# R40 register map
Vendor: Allwinner; Series: R40; File version: 0.1
CPU: CA7 0, little endian, MPU, FPU, double-precision FPU, 0 interrupt priority bits
Registers are 32-bit, read-write, reset 0x0 unless marked. A register's access mark holds for its fields unless they carry their own. Offsets are from the block's base; [hi:lo] are bit positions; {n}, {i} and the like mark numbered series; 'fields as' and 'values as' point back to an identical list.

## CCU (part 1 of 2)
Base 0x01C20000
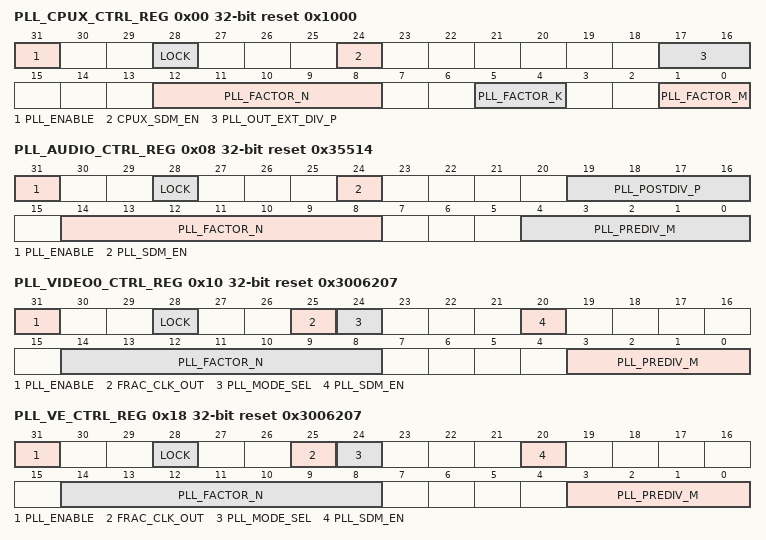
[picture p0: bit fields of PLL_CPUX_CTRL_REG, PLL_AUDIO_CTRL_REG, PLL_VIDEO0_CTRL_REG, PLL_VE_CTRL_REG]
0x00 PLL_CPUX_CTRL_REG reset 0x1000 — PLL_CPUX Control Register
  [31] PLL_ENABLE — 0: Disable 1: Enable. The PLL _CPUX = ((24MHz/K)*N)/(M*P). The PLL output is for the CPUX Clock. Note: 10<=N*K<=88. 24MHz*N*K must be in the range of 240MHz~2.1GHz. The default value of PLL _CPUX is 408MHz.
    0=Disable; 1=Enable. The PLL _CPUX = ((24MHz/K)*N)/(M*P). The PLL output is for the CPUX Clock. Note: 10<=N*K<=88. 24MHz*N*K must be in the range of 240MHz~2.1GHz. The default value of PLL _CPUX is 408MHz.
  [28] LOCK ro — 0: Unlocked 1: Locked (It indicates that the PLL has been stable.)
    0=Unlocked; 1=Locked (It indicates that the PLL has been stable.)
  [24] CPUX_SDM_EN — 0: Disable 1: Enable.
    0=Disable; 1=Enable
  [17:16] PLL_OUT_EXT_DIV_P — PLL Output External Divider P 00: /1 01: /2 10: /4 11: /.
    0=_slash_1 (/1); 1=_slash_2 (/2); 2=_slash_4 (/4); 3=_slash_
  [12:8] PLL_FACTOR_N — PLL Factor N. Factor=0, N=1 Factor=1, N=2 Factor=2, N=3 ... Factor=31,N=32.
  [5:4] PLL_FACTOR_K — PLL Factor K. (K=Factor + 1) The range is from 1 to 4.
  [1:0] PLL_FACTOR_M — PLL Factor M. (M=Factor + 1) The range is from 1 to 4.
0x08 PLL_AUDIO_CTRL_REG reset 0x35514 — PLL_AUDIO Control Register
  [31] PLL_ENABLE — 0: Disable 1: Enable. The PLL is for Audio. The PLL_AUDIO= (24MHz*N)/(M*P). The PLL_AUDIO(8X) = (24MHz*N*2)/M Note: 3<=N/M<=21. (24MHz*N)/P must be in the range of 72MHz~504MHz . PLL_AUDIO default is 24.571MHz.
    0=Disable; 1=Enable. The PLL is for Audio. The PLL_AUDIO= (24MHz*N)/(M*P). The PLL_AUDIO(8X) = (24MHz*N*2)/M Note: 3<=N/M<=21. (24MHz*N)/P must be in the range of 72MHz~504MHz . PLL_AUDIO default is 24.571MHz.
  [28] LOCK ro — 0: Unlocked 1: Locked (It indicates that the PLL has been stable.)
    values as PLL_CPUX_CTRL_REG.LOCK
  [24] PLL_SDM_EN — 0: Disable 1: Enable. In this case, the only low 4 bits of are valid (N: The range is from 1 to 16).
    0=Disable; 1=Enable. In this case, the only low 4 bits of are valid (N: The range is from 1 to 16).
  [19:16] PLL_POSTDIV_P — Post-div factor (P= Factor+1) The range is from 1 to 16.
  [14:8] PLL_FACTOR_N — PLL Factor N. Factor=0, N=1 Factor=1, N=2 ... Factor=127, N=128.
  [4:0] PLL_PREDIV_M — PLL Pre-div Factor(M = Factor+1). The range is from 1 to 32.
0x10 PLL_VIDEO0_CTRL_REG reset 0x3006207 — PLL_VIDEO0 Control Register
  [31] PLL_ENABLE — 0: Disable 1: Enable. In the integer mode, PLL_VIDEO0(1X) = (24MHz*N)/M. PLL_VIDEO0(2X) =( (24MHz*N)/M)*2. In the fractional mode, the PLL Output is select by bit 25. Note: 8<=N/M<=25 (24MHz*N)/M must be in the range of 192MHz~600MHz. PLL_VIDEO0(1X) default is 297MHz.
    0=Disable; 1=Enable. In the integer mode, PLL_VIDEO0(1X) = (24MHz*N)/M. PLL_VIDEO0(2X) =( (24MHz*N)/M)*2. In the fractional mode, the PLL Output is select by bit 25. Note: 8<=N/M<=25 (24MHz*N)/M must be in the range of 192MHz~600MHz. PLL_VIDEO0(1X) default is 297MHz.
  [28] LOCK ro — 0: Unlocked 1: Locked (It indicates that the PLL has been stable.)
    values as PLL_CPUX_CTRL_REG.LOCK
  [25] FRAC_CLK_OUT — PLL clock output when =0( factor must be set to 0); No meaning when =1. 0: PLL Output=270MHz 1: PLL Output =297MHz.
    0=PLL_Output_equals_270MHz (PLL Output=270MHz); 1=PLL Output =297MHz
  [24] PLL_MODE_SEL — 0: Fractional Mode 1: Integer Mode. Note: When in Fractional mode, the Pre Divider M should be set to 0.
    0=Fractional Mode; 1=Integer Mode. Note: When in Fractional mode, the Pre Divider M should be set to 0.
  [20] PLL_SDM_EN — 0: Disable 1: Enable.
    0=Disable; 1=Enable
  [14:8] PLL_FACTOR_N — PLL Factor N. Factor=0, N=1 Factor=1, N=2 Factor=2, N=3 ... Factor=127,N=128.
  [3:0] PLL_PREDIV_M — PLL Pre-div Factor(M = Factor+1). The range is from 1 to 16.
0x18 PLL_VE_CTRL_REG reset 0x3006207 — PLL_VE Control Register
  [31] PLL_ENABLE — 0: Disable 1: Enable. In the integer mode, The PLL_VE = (24MHz*N)/M. In the fractional mode, the PLL Output is select by . Note: 8<=N/M<=25 (24MHz*N)/M must be in the range of 192MHz~600MHz. The default value of PLL_VE is 297MHz.
    0=Disable; 1=Enable. In the integer mode, The PLL_VE = (24MHz*N)/M. In the fractional mode, the PLL Output is select by . Note: 8<=N/M<=25 (24MHz*N)/M must be in the range of 192MHz~600MHz. The default value of PLL_VE is 297MHz.
  [28] LOCK ro — 0: Unlocked 1: Locked (It indicates that the PLL has been stable.)
    values as PLL_CPUX_CTRL_REG.LOCK
  [25] FRAC_CLK_OUT — PLL clock output when =0( factor must be set to 0); No meaning when =1. 0: PLL Output = 270MHz 1: PLL Output = 297MHz.
    0=PLL_Output__equals__270MHz (PLL Output = 270MHz); 1=PLL_Output__equals__297MHz (PLL Output = 297MHz.)
  [24] PLL_MODE_SEL — 0: Fractional Mode 1: Integer Mode. Note: When in Fractional mode, the Pre Divider M should be set to 0.
    values as PLL_VIDEO0_CTRL_REG.PLL_MODE_SEL
  [20] PLL_SDM_EN — 0: Disable 1: Enable.
    0=Disable; 1=Enable
  [14:8] PLL_FACTOR_N — PLL Factor N. Factor=0, N=1 Factor=1, N=2 Factor=2, N=3 ... Factor=31,N=32 ... Factor=127,N=128.
  [3:0] PLL_PREDIV_M — PLL Pre-div Factor(M = Factor+1). The range is from 1 to 16.
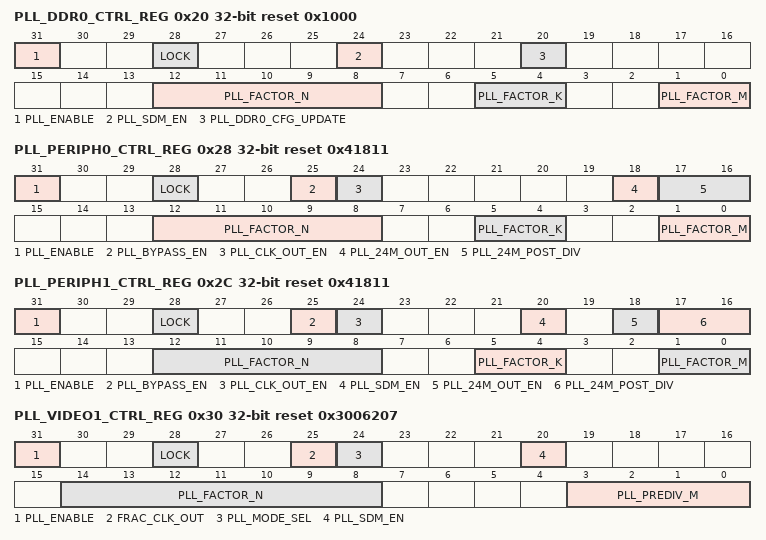
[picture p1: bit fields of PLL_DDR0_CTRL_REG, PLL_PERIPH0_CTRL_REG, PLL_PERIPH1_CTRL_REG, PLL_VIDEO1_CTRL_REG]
0x20 PLL_DDR0_CTRL_REG reset 0x1000 — PLL_DDR0 Control Register
  [31] PLL_ENABLE — 0: Disable 1: Enable. The PLL_DDR0 = (24MHz*N*K)/M. Note: 10<=N*K<=77 (24MHz*N*K) must be in the range of 240MHz~1.8GHz. The default value of PLL_DDR0 is 408MHz.
    0=Disable; 1=Enable. The PLL_DDR0 = (24MHz*N*K)/M. Note: 10<=N*K<=77 (24MHz*N*K) must be in the range of 240MHz~1.8GHz. The default value of PLL_DDR0 is 408MHz.
  [28] LOCK ro — 0: Unlocked 1: Locked (It indicates that the PLL has been stable.)
    values as PLL_CPUX_CTRL_REG.LOCK
  [24] PLL_SDM_EN — 0: Disable 1: Enable.
    0=Disable; 1=Enable
  [20] PLL_DDR0_CFG_UPDATE — PLL_DDR0 Configuration Update. When PLL_DDR0 has been changed, this bit should be set to 1 to validate the PLL, otherwise the change would be invalid. And this bit would be cleared automatically after the PLL change is valid. 0: No effect 1: Validating the PLL_DDR0.
    0=No_effect; 1=Validating the PLL_DDR0
  [12:8] PLL_FACTOR_N — PLL Factor N. Factor=0, N=1 Factor=1, N=2 Factor=2, N=3 ... Factor=31,N=32.
  [5:4] PLL_FACTOR_K — PLL Factor K.(K=Factor + 1 ) The range is from 1 to 4.
  [1:0] PLL_FACTOR_M — PLL Factor M.(M = Factor + 1 ) The range is from 1 to 4.
0x28 PLL_PERIPH0_CTRL_REG reset 0x41811 — PLL_PERIPH0 Control Register
  [31] PLL_ENABLE — 0: Disable 1: Enable. For SATA module, the output is: The PLL_PERIPH0 = 24MHz*N*K/(M*6). For other modules, the output is: The PLL_PERIPH0(1X) = 24MHz*N*K/2. The PLL_PERIPH0(2X) = 24MHz*N*K. Note: 21<=N*K<=58 The PLL_PERIPH0(2X) should be fixed to 1.2GHz, it is not recommended to vary this value arbitrarily. 24MHz*N*K clock must be in the range of 504MHz~1.4GHz. The default value of PLL_PERIPH0(2X) is 1.2GHz.
    0=Disable; 1=Enable. For SATA module, the output is: The PLL_PERIPH0 = 24MHz*N*K/(M*6). For other modules, the output is: The PLL_PERIPH0(1X) = 24MHz*N*K/2. The PLL_PERIPH0(2X) = 24MHz*N*K. Note: 21<=N*K<=58 The PLL_PERIPH0(2X) should be fixed to 1.2GHz, it is not recommended to vary this value arbitrarily. 24MHz*N*K clock must be in the range of 504MHz~1.4GHz. The default value of PLL_PERIPH0(2X) is 1.2GHz.
  [28] LOCK ro — 0: Unlocked 1: Locked (It indicates that the PLL has been stable.)
    values as PLL_CPUX_CTRL_REG.LOCK
  [25] PLL_BYPASS_EN — PLL Output Bypass Enable. 0: Disable 1: Enable. If the bypass is enabled, the PLL output is 24MHz.
    0=Disable; 1=Enable. If the bypass is enabled, the PLL output is 24MHz.
  [24] PLL_CLK_OUT_EN — PLL clock output enable.(Just for the SATA Phy) 0: Disable 1: Enable.
    0=Disable; 1=Enable
  [18] PLL_24M_OUT_EN — PLL 24MHz Output Enable. 0: Disable 1: Enable. When 25MHz crystal used, this PLL can output 24MHz.
    0=Disable; 1=Enable. When 25MHz crystal used, this PLL can output 24MHz.
  [17:16] PLL_24M_POST_DIV — PLL 24M Output Clock Post Divider (When 25MHz crystal used). 1/2/3/4.
  [12:8] PLL_FACTOR_N — PLL Factor N. Factor=0, N=1 Factor=1, N=2 Factor=2, N=3 ... Factor=31,N=32.
  [5:4] PLL_FACTOR_K — PLL Factor K.(K=Factor + 1 ) The range is from 1 to 4.
  [1:0] PLL_FACTOR_M — The range is from 1 to 4.
0x2C PLL_PERIPH1_CTRL_REG reset 0x41811 — PLL_PERIPH1 Control Register
  [31] PLL_ENABLE — 0: Disable 1: Enable. The PLL_PERIPH1(1X) = 24MHz*N*K/2. The PLL_PERIPH1(2X) = 24MHz*N*K. Note: 21<=N*K<=58 PLL_PERIPH1(2X) should be fixed to 1.2GHz, it is not recommended to vary this value arbitrarily. 24MHz*N*K must be in the range of 504MHz~1.4GHz. The default value of PLL_PERIPH1(2X) is 1.2GHz.
    0=Disable; 1=Enable. The PLL_PERIPH1(1X) = 24MHz*N*K/2. The PLL_PERIPH1(2X) = 24MHz*N*K. Note: 21<=N*K<=58 PLL_PERIPH1(2X) should be fixed to 1.2GHz, it is not recommended to vary this value arbitrarily. 24MHz*N*K must be in the range of 504MHz~1.4GHz. The default value of PLL_PERIPH1(2X) is 1.2GHz.
  [28] LOCK ro — 0: Unlocked 1: Locked (It indicates that the PLL has been stable.)
    values as PLL_CPUX_CTRL_REG.LOCK
  [25] PLL_BYPASS_EN — PLL Output Bypass Enable. 0: Disable 1: Enable. If the bypass is enabled, the PLL output is 24MHz.
    values as PLL_PERIPH0_CTRL_REG.PLL_BYPASS_EN
  [24] PLL_CLK_OUT_EN — PLL clock output enable.(Just for the SATA Phy) 0: Disable 1: Enable.
    0=Disable; 1=Enable
  [20] PLL_SDM_EN — 0: Disable 1: Enable.
    0=Disable; 1=Enable
  [18] PLL_24M_OUT_EN — PLL 24MHz Output Enable. 0: Disable 1: Enable. When 25MHz crystal used, this PLL can output 24MHz.
    values as PLL_PERIPH0_CTRL_REG.PLL_24M_OUT_EN
  [17:16] PLL_24M_POST_DIV — PLL 24M Output Clock Post Divider (When 25MHz crystal used). 1/2/3/4.
  [12:8] PLL_FACTOR_N — PLL Factor N. Factor=0, N=1 Factor=1, N=2 Factor=2, N=3 ... Factor=31,N=32.
  [5:4] PLL_FACTOR_K — PLL Factor K.(K=Factor + 1 ) The range is from 1 to 4.
  [1:0] PLL_FACTOR_M — The range is from 1 to 4.
0x30 PLL_VIDEO1_CTRL_REG reset 0x3006207 — PLL_VIDEO1 Control Register
  [31] PLL_ENABLE — 0: Disable 1: Enable. In the integer mode, PLL_VIDEO1(1X) = (24MHz*N)/M. PLL_VIDEO1(2X) =( (24MHz*N)/M)*2. In the fractional mode, the PLL Output is selected by . Note: 8<=N/M<=25 (24MHz*N)/M must be in the range of 192MHz~600MHz. The default value of PLL_VIDEO1(1X) is 297MHz.
    0=Disable; 1=Enable. In the integer mode, PLL_VIDEO1(1X) = (24MHz*N)/M. PLL_VIDEO1(2X) =( (24MHz*N)/M)*2. In the fractional mode, the PLL Output is selected by . Note: 8<=N/M<=25 (24MHz*N)/M must be in the range of 192MHz~600MHz. The default value of PLL_VIDEO1(1X) is 297MHz.
  [28] LOCK ro — 0: Unlocked 1: Locked (It indicates that the PLL has been stable.)
    values as PLL_CPUX_CTRL_REG.LOCK
  [25] FRAC_CLK_OUT — PLL clock output when =0( factor must be set to 0); No meaning when =1. 0: PLL Output=270MHz 1: PLL Output =297MHz.
    values as PLL_VIDEO0_CTRL_REG.FRAC_CLK_OUT
  [24] PLL_MODE_SEL — 0: Fractional Mode 1: Integer Mode. Note: When in Fractional mode, the Per Divider M should be set to 0.
    0=Fractional Mode; 1=Integer Mode. Note: When in Fractional mode, the Per Divider M should be set to 0.
  [20] PLL_SDM_EN — 0: Disable 1: Enable.
    0=Disable; 1=Enable
  [14:8] PLL_FACTOR_N — PLL Factor N. Factor=0, N=1 Factor=1, N=2 Factor=2, N=3 ... Factor=127,N=128.
  [3:0] PLL_PREDIV_M — PLL Pre-div Factor(M = Factor+1). The range is from 1 to 16.
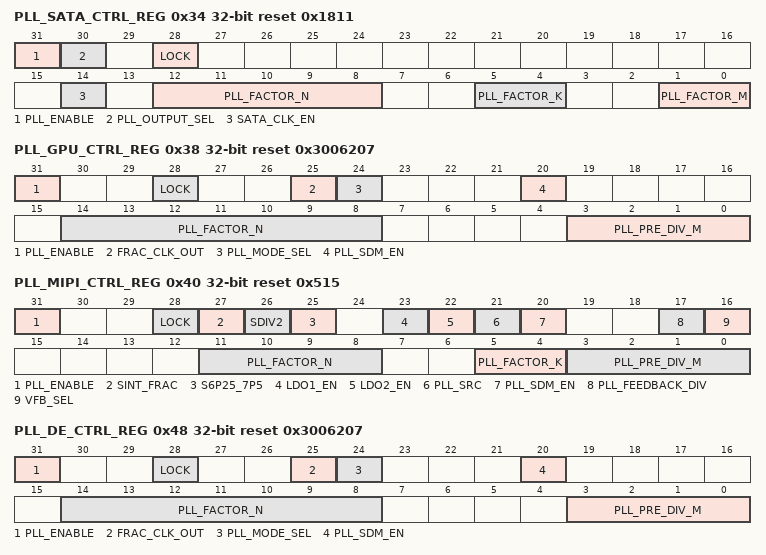
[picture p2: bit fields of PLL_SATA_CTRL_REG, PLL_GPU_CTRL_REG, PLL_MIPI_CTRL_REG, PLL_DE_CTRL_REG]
0x34 PLL_SATA_CTRL_REG reset 0x1811 — PLL_SATA Control Register
  [31] PLL_ENABLE — 0: Disable 1: Enable. The PLL_SATA = 24MHz*N*K/(M*6). The PLL should be in the range of 8 MHz ~ 300 MHz. The default value is 100 MHz.
    0=Disable; 1=Enable. The PLL_SATA = 24MHz*N*K/(M*6). The PLL should be in the range of 8 MHz ~ 300 MHz. The default value is 100 MHz.
  [30] PLL_OUTPUT_SEL — 0: PLL output from SATA_PLL 1: PLL output from PLL_PERIPH0
    0=PLL_output_from_SATA_PLL; 1=PLL_output_from_PLL_PERIPH0
  [28] LOCK ro — 0: Unlocked 1: Locked (It indicates that the PLL has been stable.)
    values as PLL_CPUX_CTRL_REG.LOCK
  [14] SATA_CLK_EN — SATA Clock Output Enable. 0: Disable 1: Enable.
    0=Disable; 1=Enable
  [12:8] PLL_FACTOR_N — PLL Factor N. Factor=0, N=1 Factor=1, N=2 Factor=2, N=3 ... Factor=31,N=32.
  [5:4] PLL_FACTOR_K — PLL Factor K.(K=Factor + 1 ) The range is from 1 to 4.
  [1:0] PLL_FACTOR_M — (M=Factor + 1 ) The range is from 1 to 4.
0x38 PLL_GPU_CTRL_REG reset 0x3006207 — PLL_GPU Control Register
  [31] PLL_ENABLE — 0: Disable 1: Enable. In the integer mode, The PLL_GPU = (24MHz*N)/M. In the fractional mode, the PLL Output is selected by . Note: 8<=N/M<=25 (24MHz*N)/M must be in the range of 192 MHz ~ 600 MHz. The default value of PLL_GPU is 297 MHz.
    0=Disable; 1=Enable. In the integer mode, The PLL_GPU = (24MHz*N)/M. In the fractional mode, the PLL Output is selected by . Note: 8<=N/M<=25 (24MHz*N)/M must be in the range of 192 MHz ~ 600 MHz. The default value of PLL_GPU is 297 MHz.
  [28] LOCK ro — 0: Unlocked 1: Locked (It indicates that the PLL has been stable.)
    values as PLL_CPUX_CTRL_REG.LOCK
  [25] FRAC_CLK_OUT — PLL clock output when =0( factor must be set to 0); no meaning when =1. 0: PLL Output=270MHz 1: PLL Output=297MHz.
    0=PLL_Output_equals_270MHz (PLL Output=270MHz); 1=PLL_Output_equals_297MHz (PLL Output=297MHz.)
  [24] PLL_MODE_SEL — 0: Fractional Mode. 1: Integer Mode. Note: When in Fractional mode, the Per Divider M should be set to 0.
    values as PLL_VIDEO1_CTRL_REG.PLL_MODE_SEL
  [20] PLL_SDM_EN — 0: Disable 1: Enable.
    0=Disable; 1=Enable
  [14:8] PLL_FACTOR_N — PLL Factor N. Factor=0, N=1 Factor=1, N=2 Factor=2, N=3 ... Factor=127,N=128.
  [3:0] PLL_PRE_DIV_M — PLL Pre Divider (M = Factor+1). The range is from 1 to 16.
0x40 PLL_MIPI_CTRL_REG reset 0x515 — PLL_MIPI Control Register
  [31] PLL_ENABLE — 0: Disable 1: Enable. The PLL_MIPI= (PLL_VIDEO0(1X)*N*K)/M when =0 (MIPI mode). When VFB_SEL=1, the PLL Output is depend on these bits: sint_frac,sdiv2, s6p25_7p5 , pll_feedback_div.6 Note: K≥2; M/N<=3; (PLL_VIDEO0)/M≥24MHz; PLL_MIPI must be in the range of 500 MHz ~ 1.4 GHz. The default value of PLL_MIPI is 594 MHz.
    0=Disable; 1=Enable. The PLL_MIPI= (PLL_VIDEO0(1X)*N*K)/M when =0 (MIPI mode). When VFB_SEL=1, the PLL Output is depend on these bits: sint_frac,sdiv2, s6p25_7p5 , pll_feedback_div.6 Note: K≥2; M/N<=3; (PLL_VIDEO0)/M≥24MHz; PLL_MIPI must be in the range of 500 MHz ~ 1.4 GHz. The default value of PLL_MIPI is 594 MHz.
  [28] LOCK ro — 0: Unlocked 1: Locked (It indicates that the PLL has been stable.)
    values as PLL_CPUX_CTRL_REG.LOCK
  [27] SINT_FRAC — When =1, PLL mode control, otherwise no meaning. 0: Integer Mode 1: Fractional Mode.
    0=Integer Mode; 1=Fractional Mode
  [26] SDIV2 — PLL clock output when =1; no meaning when =0 0: PLL Output 1: PLL Output X2.
  [25] S6P25_7P5 — PLL Output is selected by this bit when =1 and =1, otherwise no meaning. 0: PLL Output=PLL Input*6.25 1: PLL Output= PLL Input *7.5.
    0=PLL_Output_equals_PLL (PLL Output=PLL Input*6.25); 1=PLL_Output_equals_ (PLL Output= PLL Input *7.5.)
  [23] LDO1_EN — On-chip LDO1 Enable.
  [22] LDO2_EN — On-chip LDO2 Enable.
  [21] PLL_SRC — PLL Source Select. 0: VIDEO0 PLL 1: /.
    0=VIDEO0 (VIDEO0 PLL); 1=_slash_
  [20] PLL_SDM_EN — 0: Disable 1: Enable.
    0=Disable; 1=Enable
  [17] PLL_FEEDBACK_DIV — PLL feed-back divider control. PLL clock output when =1; no meaning when =0 0: Divided by 5 1: Divided by 7.
    0=Divided_by_5; 1=Divided_by_7
  [16] VFB_SEL — 0: MIPI Mode(N, K, M valid) 1: HDMI Mode(sint_frac,sdiv2,s6p25_7p5 , pll_feedback_div valid)
    0=MIPI (MIPI Mode(N, K, M valid)); 1=HDMI (HDMI Mode(sint_frac,sdiv2,s6p25_7p5 , pll_feedback_div valid))
  [11:8] PLL_FACTOR_N — PLL Factor N. Factor=0, N=1 Factor=1, N=2 ... Factor=15,N=16;
  [5:4] PLL_FACTOR_K — PLL Factor K.(K=Factor + 1 ) The range is from 2 to 4.
  [3:0] PLL_PRE_DIV_M — PLL Pre Divider (M = Factor+1). The range is from 1 to 16.
0x48 PLL_DE_CTRL_REG reset 0x3006207 — PLL_DE Control Register
  [31] PLL_ENABLE — 0: Disable 1: Enable. In the integer mode, The PLL_DE = (24MHz*N)/M. In the fractional mode, the PLL Output is selected by . Note: 8<=N/M<=25 (24MHz*N)/M must be in the range of 192MHz~600MHz. The default value of PLL_DE is 297MHz.
    0=Disable; 1=Enable. In the integer mode, The PLL_DE = (24MHz*N)/M. In the fractional mode, the PLL Output is selected by . Note: 8<=N/M<=25 (24MHz*N)/M must be in the range of 192MHz~600MHz. The default value of PLL_DE is 297MHz.
  [28] LOCK ro — 0: Unlocked 1: Locked (It indicates that the PLL has been stable.)
    values as PLL_CPUX_CTRL_REG.LOCK
  [25] FRAC_CLK_OUT — PLL clock output when =0( factor must be set to 0); no meaning when =1. 0: PLL Output=270MHz 1: PLL Output =297MHz.
    values as PLL_VIDEO0_CTRL_REG.FRAC_CLK_OUT
  [24] PLL_MODE_SEL — 0: Fractional Mode 1: Integer Mode. Note: When in Fractional mode, the Pre Divider M should be set to 0.
    values as PLL_VIDEO0_CTRL_REG.PLL_MODE_SEL
  [20] PLL_SDM_EN — 0: Disable 1: Enable.
    0=Disable; 1=Enable
  [14:8] PLL_FACTOR_N — PLL Factor N. Factor=0, N=1 Factor=1, N=2 Factor=2, N=3 ... Factor=0x7F,N=128.
  [3:0] PLL_PRE_DIV_M — PLL Per Divider (M = Factor+1). The range is from 1 to 16.
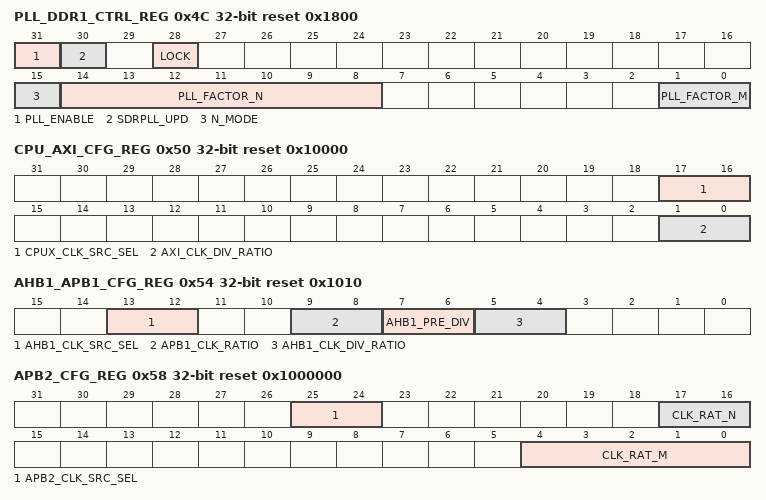
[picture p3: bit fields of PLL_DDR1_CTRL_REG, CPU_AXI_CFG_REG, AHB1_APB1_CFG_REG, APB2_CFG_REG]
0x4C PLL_DDR1_CTRL_REG reset 0x1800 — PLL_DDR1 Control Register
  [31] PLL_ENABLE — 0: Disable 1: Enable. The PLL_DDR1 = 24MHz*N/M. Note: 16<=N<=75. 24MHz*N/M must be in the range of 192 MHz ~ 1.6 GHz. Its default value is 600 MHz.
    0=Disable; 1=Enable. The PLL_DDR1 = 24MHz*N/M. Note: 16<=N<=75. 24MHz*N/M must be in the range of 192 MHz ~ 1.6 GHz. Its default value is 600 MHz.
  [30] SDRPLL_UPD — SDRPLL Configuration Update. Note: When PLL_DDR1 has changed, this bit should be set to 1 to validate the PLL, otherwise the change is invalid. It will be automatically cleared after the PLL is valid. 0: No effect 1: To validate the PLL_DDR1.
    0=No_effect; 1=To validate the PLL_DDR1
  [28] LOCK ro — 0: Unlocked 1: Locked (It indicates that the PLL has been stable.)
    values as PLL_CPUX_CTRL_REG.LOCK
  [15] N_MODE — 0: New mode 1: Original mode If new mode, avoid config N=0 mistake.
    0=New_mode; 1=Original mode If new mode, avoid config N=0 mistake
  [14:8] PLL_FACTOR_N — N= Factor +1. The range is from 0 to 127
  [1:0] PLL_FACTOR_M — M= Factor +1. The range is from 0 to 4
0x50 CPU_AXI_CFG_REG reset 0x10000 — CPUX/AXI Configuration Register
  [17:16] CPUX_CLK_SRC_SEL — CPUX Clock Source Select. CPUX Clock = Clock Source 00: LOSC 01: OSC24M 1X: PLL_CPUX If the clock source is changed, there need to wait for 8 present running clock cycles at most.
    0=LOSC; 1=OSC24M; 2=PLL_CPUX (PLL_CPUX If the clock source is changed, there need to wait for 8 present running clock cycles at most.)
  [1:0] AXI_CLK_DIV_RATIO — AXI Clock Divide Ratio. AXI Clock source is CPU clock source. 00: /1 01: /2 10: /3 11: /4.
    0=_slash_1 (/1); 1=_slash_2 (/2); 2=_slash_3 (/3); 3=_slash_4 (/4.)
0x54 AHB1_APB1_CFG_REG reset 0x1010 — AHB1/APB1 Configuration Register
  [13:12] AHB1_CLK_SRC_SEL — 00: LOSC 01: OSC24M 10: AXI 11: PLL_PERIPH0(1X)/AHB1_PRE_DIV.
    0=LOSC; 1=OSC24M; 2=AXI; 3=PLL_PERIPH0_openingparen_1X_closingparen__slash_AHB1_PRE_DIV (PLL_PERIPH0(1X)/AHB1_PRE_DIV.)
  [9:8] APB1_CLK_RATIO — APB1 Clock Divide Ratio. APB1 clock source is AHB1 clock. 00: /2 01: /2 10: /4 11: /8.
  [7:6] AHB1_PRE_DIV — AHB1 Clock Pre Divide Ratio 00: /1 01: /2 10: /3 11: /4.
    values as CPU_AXI_CFG_REG.AXI_CLK_DIV_RATIO
  [5:4] AHB1_CLK_DIV_RATIO — AHB1 Clock Divide Ratio. 00: /1 01: /2 10: /4 11: /8.
    0=_slash_1 (/1); 1=_slash_2 (/2); 2=_slash_4 (/4); 3=_slash_8 (/8.)
0x58 APB2_CFG_REG reset 0x1000000
  [25:24] APB2_CLK_SRC_SEL — APB2 Clock Source Select 00: LOSC 01: OSC24M 1X: PLL_PERIPH0(2X). This clock is used for some special module apbclk(UART, TWI, PS2). Because these modules need special clock rate even if the apb1clk changed.
    0=LOSC; 1=OSC24M; 2=PLL_PERIPH0_openingparen_2X_closingparen_ (PLL_PERIPH0(2X). This clock is used for some special module apbclk(UART, TWI, PS2). Because these modules need special clock rate even if the apb1clk changed.)
  [17:16] CLK_RAT_N — Clock Per Divide Ratio (n) 00: /1 01: /2 10: /4 11: /8.
    values as AHB1_APB1_CFG_REG.AHB1_CLK_DIV_RATIO
  [4:0] CLK_RAT_M — Clock Divide Ratio (m) The pre-divided clock is divided by (m+1). The divider is from 1 to 32.
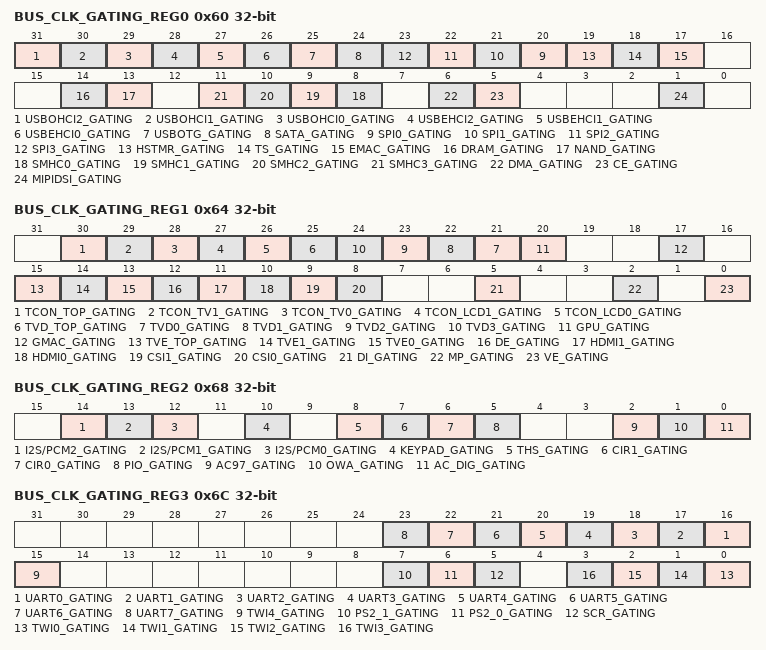
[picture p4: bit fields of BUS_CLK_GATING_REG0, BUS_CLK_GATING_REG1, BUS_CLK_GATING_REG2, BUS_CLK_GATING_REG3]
0x60 BUS_CLK_GATING_REG0 — Bus Clock Gating Register 0
  [all] fields
    0=Mask; 1=Pass
  [31] USBOHCI2_GATING — Gating Clock for USB OHCI1 0: Mask 1: Pass
  [30] USBOHCI1_GATING — Gating Clock for USB OHCI1 0: Mask 1: Pass
  [29] USBOHCI0_GATING — Gating Clock for USB OHCI0 0: Mask 1: Pass
  [28] USBEHCI2_GATING — Gating Clock for USB EHCI1 0: Mask 1: Pass
  [27] USBEHCI1_GATING — Gating Clock for USB EHCI1 0: Mask 1: Pass
  [26] USBEHCI0_GATING — Gating Clock for USB EHCI0 0: Mask 1: Pass
  [25] USBOTG_GATING — Gating Clock for USB OTG 0: Mask 1: Pass
  [24] SATA_GATING — Gating Clock for SATA 0: Mask 1: Pass.
  [n+20] SPI{n}_GATING (n=0..3) — Gating Clock for SPI{n} 0: Mask 1: Pass.
  [19] HSTMR_GATING — Gating Clock for High Speed Timer 0: Mask 1: Pass.
  [18] TS_GATING — Gating Clock for TS 0: Mask 1: Pass
  [17] EMAC_GATING — Gating Clock for EMAC 0: Mask 1: Pass
  [14] DRAM_GATING — Gating Clock for DRAM 0: Mask 1: Pass.
  [13] NAND_GATING — Gating Clock for NAND 0: Mask 1: Pass.
  [n+8] SMHC{n}_GATING (n=0..3) — Gating Clock for SMHC{n} 0: Mask 1: Pass.
  [6] DMA_GATING — Gating Clock for DMA 0: Mask 1: Pass.
  [5] CE_GATING — Gating Clock for CE 0: Mask 1: Pass.
  [1] MIPIDSI_GATING — Gating Clock for MIPI DSI 0: Mask 1: Pass
0x64 BUS_CLK_GATING_REG1 — Bus Clock Gating Register 1
  [30] TCON_TOP_GATING — 0: Mask 1: Pass
    0=Mask; 1=Pass
  [29] TCON_TV1_GATING — 0: Mask 1: Pass
    0=Mask; 1=Pass
  [28] TCON_TV0_GATING — 0: Mask 1: Pass
    0=Mask; 1=Pass
  [27] TCON_LCD1_GATING — 0: Mask 1: Pass
    0=Mask; 1=Pass
  [26] TCON_LCD0_GATING — 0: Mask 1: Pass
    0=Mask; 1=Pass
  [25] TVD_TOP_GATING — 0:Mask 1:Pass
  [n+21] TVD{n}_GATING (n=0..3) — 0: Mask 1: Pass
    0=Mask; 1=Pass
  [20] GPU_GATING — Gating Clock for GPU 0: Mask 1: Pass.
    0=Mask; 1=Pass
  [17] GMAC_GATING — Gating Clock for GMAC 0: Mask 1: Pass.
    0=Mask; 1=Pass
  [15] TVE_TOP_GATING — 0: Mask 1: Pass
    0=Mask; 1=Pass
  [14] TVE1_GATING — 0: Mask 1: Pass
    0=Mask; 1=Pass
  [13] TVE0_GATING — 0: Mask 1: Pass
    0=Mask; 1=Pass
  [12] DE_GATING — Gating Clock For DE 0: Mask 1: Pass.
    0=Mask; 1=Pass
  [11] HDMI1_GATING — 0: Mask 1: Pass.
    0=Mask; 1=Pass
  [10] HDMI0_GATING — 0: Mask 1: Pass.
    0=Mask; 1=Pass
  [9] CSI1_GATING — Gating Clock for CSI1 0: Mask 1: Pass.
    0=Mask; 1=Pass
  [8] CSI0_GATING — Gating Clock for CSI0 0: Mask 1: Pass.
    0=Mask; 1=Pass
  [5] DI_GATING — Gating Clock for DEINTERLACE 0: Mask 1: Pass
    0=Mask; 1=Pass
  [2] MP_GATING — Gating Clock for MP 0: Mask 1: Pass
    0=Mask; 1=Pass
  [0] VE_GATING — Gating Clock for VE 0: Mask 1: Pass.
    0=Mask; 1=Pass
0x68 BUS_CLK_GATING_REG2 — Bus Clock Gating Register 2
  [all] fields
    0=Mask; 1=Pass
  [14] I2S/PCM2_GATING — Gating Clock for I2S/PCM2 0: Mask 1: Pass.
  [13] I2S/PCM1_GATING — Gating Clock for I2S/PCM1 0: Mask 1: Pass.
  [12] I2S/PCM0_GATING — Gating Clock for I2S/PCM0 0: Mask 1: Pass.
  [10] KEYPAD_GATING — Gating Clock for KEYPAD 0: Mask 1: Pass.
  [8] THS_GATING — Gating Clock for THS 0: Mask 1: Pass
  [7] CIR1_GATING — Gating Clock for CIR1 0: Mask 1: Pass
  [6] CIR0_GATING — Gating Clock for CIR0 0: Mask 1: Pass
  [5] PIO_GATING — Gating Clock for PIO 0: Mask 1: Pass.
  [2] AC97_GATING — Gating Clock for AC97 0: Mask 1: Pass
  [1] OWA_GATING — Gating Clock for OWA 0: Mask 1: Pass
  [0] AC_DIG_GATING — Gating Clock for AC Digital 0: Mask 1: Pass
0x6C BUS_CLK_GATING_REG3 — Bus Clock Gating Register 3
  [all] fields
    0=Mask; 1=Pass
  [n+16] UART{n}_GATING (n=0..7) — Gating Clock for UART{n} 0: Mask 1: Pass.
  [15] TWI4_GATING — Gating Clock for TWI4 0: Mask 1: Pass.
  [7] PS2_1_GATING — Gating Clock for PS2_1 0: Mask 1: Pass
  [6] PS2_0_GATING — Gating Clock for PS2_0 0: Mask 1: Pass
  [5] SCR_GATING — Gating Clock for SCR 0: Mask 1: Pass
  [n] TWI{n}_GATING (n=0..3) — Gating Clock for TWI{n} 0: Mask 1: Pass.
0x70 BUS_CLK_GATING_REG4 — Bus Clock Gating Register 4
  [7] DBGSYS_GATING — Gating Clock for DBGSYS 0: Mask 1: Pass
    0=Mask; 1=Pass
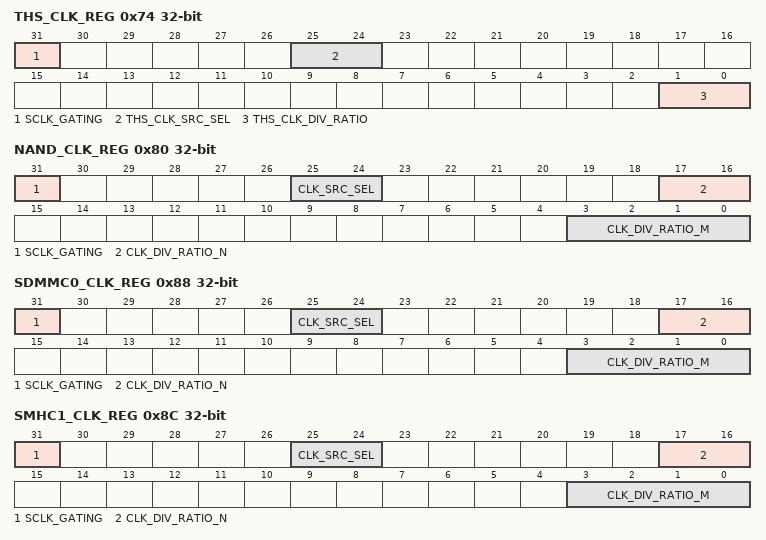
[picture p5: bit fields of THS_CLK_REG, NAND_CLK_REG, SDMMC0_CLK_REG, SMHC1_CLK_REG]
0x74 THS_CLK_REG — THS Clock Register
  [31] SCLK_GATING — Gating Special Clock. 0: Clock is OFF 1: Clock is ON This special clock = / .
    0=OFF (Clock is OFF); 1=ON (Clock is ON This special clock = / .)
  [25:24] THS_CLK_SRC_SEL — Clock Source Select 00: OSC24M Others: /
    0=OSC24M (OSC24M Others: /)
  [1:0] THS_CLK_DIV_RATIO — THS clock divide ratio. 00: /1 01: /2 10: /4 11: /8
    0=_slash_1 (/1); 1=_slash_2 (/2); 2=_slash_4 (/4); 3=_slash_8 (/8)
0x80 NAND_CLK_REG — NAND Clock Register
  [31] SCLK_GATING — Gating Special Clock(Max Clock = 200MHz) 0: Clock is OFF 1: Clock is ON. SCLK = / / .
    0=OFF (Clock is OFF); 1=ON (Clock is ON. SCLK = / / .)
  [25:24] CLK_SRC_SEL — Clock Source Select 00: OSC24M 01: PLL_PERIPH0(1X) 10: PLL_PERIPH1(1X) 11: /.
    0=OSC24M; 1=PLL_PERIPH0_openingparen_1X_closingparen_ (PLL_PERIPH0(1X)); 2=PLL_PERIPH1_openingparen_1X_closingparen_ (PLL_PERIPH1(1X)); 3=_slash_
  [17:16] CLK_DIV_RATIO_N — Clock Pre Divide Ratio (n) 00: /1 01: /2 10: /4 11: /8.
    values as AHB1_APB1_CFG_REG.AHB1_CLK_DIV_RATIO
  [3:0] CLK_DIV_RATIO_M — Clock Divide Ratio (m) The pre-divided clock is divided by (m+1). The divider M is from 1 to 16.
0x88 SDMMC0_CLK_REG — SDMMC0 Clock Register
  [31] SCLK_GATING — Gating Special Clock 0: Clock is OFF 1: Clock is ON. SCLK = / / .
    0=OFF (Clock is OFF); 1=ON (Clock is ON. SCLK = / / .)
  [25:24] CLK_SRC_SEL — Clock Source Select 00: OSC24M 01: PLL_PERIPH0(2X) 10: PLL_PERIPH1(2X) 11: /.
    0=OSC24M; 1=PLL_PERIPH0_openingparen_2X_closingparen_ (PLL_PERIPH0(2X)); 2=PLL_PERIPH1_openingparen_2X_closingparen_ (PLL_PERIPH1(2X)); 3=_slash_
  [17:16] CLK_DIV_RATIO_N — Clock Pre Divide Ratio (n) 00: /1 01: /2 10: /4 11: /8.
    values as AHB1_APB1_CFG_REG.AHB1_CLK_DIV_RATIO
  [3:0] CLK_DIV_RATIO_M — Clock Divide Ratio (m) The pre-divided clock is divided by (m+1). The divider is from 1 to 16.
0x8C SMHC1_CLK_REG
  [31] SCLK_GATING — Gating Special Clock 0: Clock is OFF 1: Clock is ON. SCLK = / / .
    0=OFF (Clock is OFF); 1=ON (Clock is ON. SCLK = / / .)
  [25:24] CLK_SRC_SEL — Clock Source Select 00: OSC24M 01: PLL_PERIPH0(2X) 10: PLL_PERIPH1(2X) 11: /
    0=OSC24M; 1=PLL_PERIPH0_openingparen_2X_closingparen_ (PLL_PERIPH0(2X)); 2=PLL_PERIPH1_openingparen_2X_closingparen_ (PLL_PERIPH1(2X))
  [17:16] CLK_DIV_RATIO_N — Clock Pre Divide Ratio (n) 00: /1 01: /2 10: /4 11: /8
    values as THS_CLK_REG.THS_CLK_DIV_RATIO
  [3:0] CLK_DIV_RATIO_M — Clock Divide Ratio (m) The pre-divided clock is divided by (m+1). The divider is from 1 to 16.
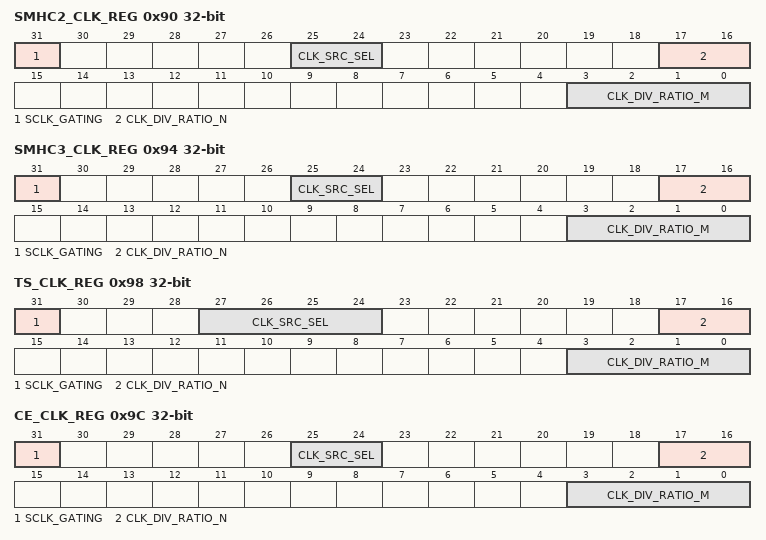
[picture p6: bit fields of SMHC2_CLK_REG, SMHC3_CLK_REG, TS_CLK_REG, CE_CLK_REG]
0x90 SMHC2_CLK_REG
  fields as SMHC1_CLK_REG
0x94 SMHC3_CLK_REG
  [31] SCLK_GATING — Gating Special Clock 0: Clock is OFF 1: Clock is ON. SCLK = / / .
    0=OFF (Clock is OFF); 1=ON (Clock is ON. SCLK = / / .)
  [25:24] CLK_SRC_SEL — Clock Source Select 00: OSC24M 01: PLL_PERIPH0(2X) 10: PLL_PERIPH1(2X) 11: /
    values as SMHC1_CLK_REG.CLK_SRC_SEL
  [17:16] CLK_DIV_RATIO_N — Clock Pre Divide Ratio (n) 00: /1 01: /2 10: /4 11: /8.
    values as AHB1_APB1_CFG_REG.AHB1_CLK_DIV_RATIO
  [3:0] CLK_DIV_RATIO_M — Clock Divide Ratio (m) The pre-divided clock is divided by (m+1). The divider is from 1 to 16.
0x98 TS_CLK_REG — TS Clock Register
  [31] SCLK_GATING — Gating of SCLK (Max Clock = 200MHz). 0: Clock is OFF 1: Clock is ON SCLK = / / .
    0=OFF (Clock is OFF); 1=ON (Clock is ON SCLK = / / .)
  [27:24] CLK_SRC_SEL — Clock Source Select 0000: OSC24M 0001: PLL_PERIPH0(1X) Others: /
    0=OSC24M; 1=PLL_PERIPH0_openingparen_1X_closingparen_ (PLL_PERIPH0(1X) Others: /)
  [17:16] CLK_DIV_RATIO_N — Clock pre-divide ratio (n) The select clock source is pre-divided by 2^n. The divider is 1/2/4/8.
  [3:0] CLK_DIV_RATIO_M — Clock divide ratio (m) The pre-divided clock is divided by (m+1). The divider is from 1 to 16.
0x9C CE_CLK_REG — CE Clock Register
  [31] SCLK_GATING — Gating Special Clock(Max Clock = 400MHz) 0: Clock is OFF 1: Clock is ON. SCLK = / / .
    0=OFF (Clock is OFF); 1=ON (Clock is ON. SCLK = / / .)
  [25:24] CLK_SRC_SEL — Clock Source Select 00: OSC24M 01: PLL_PERIPH0(2X) 10: PLL_PERIPH1(2X) 11: /
    values as SMHC1_CLK_REG.CLK_SRC_SEL
  [17:16] CLK_DIV_RATIO_N — Clock Pre Divide Ratio (n) 00: /1 01: /2 10: /4 11: /8.
    values as AHB1_APB1_CFG_REG.AHB1_CLK_DIV_RATIO
  [3:0] CLK_DIV_RATIO_M — Clock divide ratio (m) The pre-divided clock is divided by (m+1). The divider is from 1 to 16.
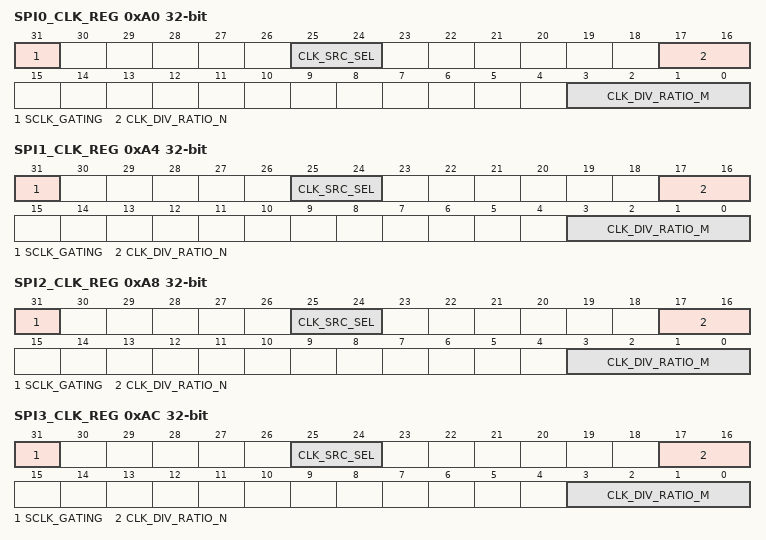
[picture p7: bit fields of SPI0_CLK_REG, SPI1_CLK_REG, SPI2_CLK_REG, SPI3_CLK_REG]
0xA0 SPI0_CLK_REG — SPI0 Clock Register
  [31] SCLK_GATING — Gating Special Clock(Max Clock = 200MHz) 0: Clock is OFF 1: Clock is ON. SCLK = / / .
    0=OFF (Clock is OFF); 1=ON (Clock is ON. SCLK = / / .)
  [25:24] CLK_SRC_SEL — Clock Source Select 00: OSC24M 01: PLL_PERIPH0(1X) 10: PLL_PERIPH1(1X) 11: /
    0=OSC24M; 1=PLL_PERIPH0_openingparen_1X_closingparen_ (PLL_PERIPH0(1X)); 2=PLL_PERIPH1_openingparen_1X_closingparen_ (PLL_PERIPH1(1X))
  [17:16] CLK_DIV_RATIO_N — Clock Pre Divide Ratio (n) 00: /1 01: /2 10: /4 11: /8.
    values as AHB1_APB1_CFG_REG.AHB1_CLK_DIV_RATIO
  [3:0] CLK_DIV_RATIO_M — Clock Divide Ratio (m) The pre-divided clock is divided by (m+1). The divider is from 1 to 16.
0xA4 SPI1_CLK_REG — SPI1 Clock Register
  [31] SCLK_GATING — Gating Special Clock(Max Clock = 200MHz) 0: Clock is OFF 1: Clock is ON SCLK= / / .
    0=OFF (Clock is OFF); 1=ON (Clock is ON SCLK= / / .)
  [25:24] CLK_SRC_SEL — Clock Source Select 00: OSC24M 01: PLL_PERIPH0(1X) 10: PLL_PERIPH1(1X) 11: /
    values as SPI0_CLK_REG.CLK_SRC_SEL
  [17:16] CLK_DIV_RATIO_N — Clock Pre Divide Ratio (n) 00: /1 01: /2 10: /4 11: /8.
    values as AHB1_APB1_CFG_REG.AHB1_CLK_DIV_RATIO
  [3:0] CLK_DIV_RATIO_M — Clock Divide Ratio (m) The pre-divided clock is divided by (m+1). The divider is from 1 to 16.
0xA8 SPI2_CLK_REG — SPI2 Clock Register
  fields as SPI1_CLK_REG
0xAC SPI3_CLK_REG — SPI3 Clock Register
  [31] SCLK_GATING — Gating Special Clock(Max Clock = 200MHz) 0: Clock is OFF 1: Clock is ON SCLK= / / .
    0=OFF (Clock is OFF); 1=ON (Clock is ON SCLK= / / .)
  [25:24] CLK_SRC_SEL — Clock Source Select 00: OSC24M 01: PLL_PERIPH0(1X) 10: PLL_PERIPH1(1X) 11: /
    values as SPI0_CLK_REG.CLK_SRC_SEL
  [17:16] CLK_DIV_RATIO_N — Clock Pre Divide Ratio (n) 00: /1 01: /2 10: /4 11: /8
    values as THS_CLK_REG.THS_CLK_DIV_RATIO
  [3:0] CLK_DIV_RATIO_M — Clock Divide Ratio (m) The pre-divided clock is divided by (m+1). The divider is from 1 to 16.
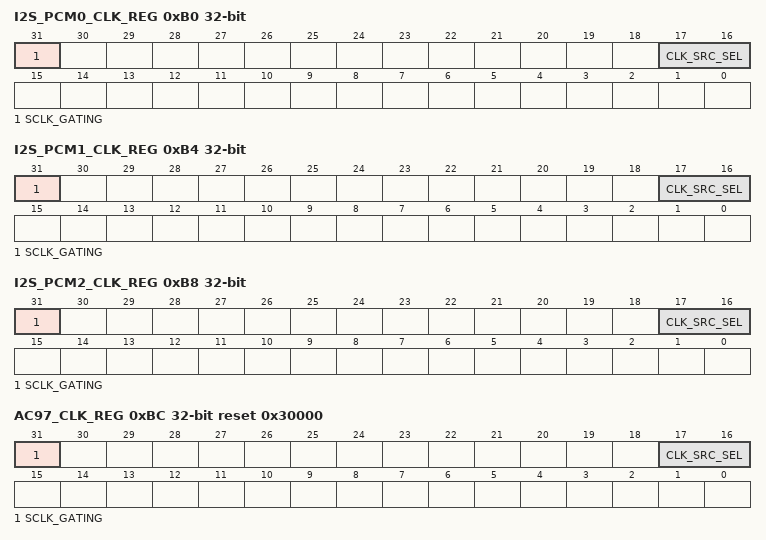
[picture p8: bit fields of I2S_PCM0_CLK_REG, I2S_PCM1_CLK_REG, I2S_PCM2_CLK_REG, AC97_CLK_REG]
0xB0 I2S_PCM0_CLK_REG
  [31] SCLK_GATING — Gating Special Clock(Max Clock = 200MHz) 0: Clock is OFF 1: Clock is ON.
    0=OFF (Clock is OFF); 1=ON (Clock is ON.)
  [17:16] CLK_SRC_SEL — 00: PLL_AUDIO (8X) 01: PLL_AUDIO(8X)/2 10: PLL_AUDIO(8X)/4 11: PLL_AUDIO.
0xB4 I2S_PCM1_CLK_REG
  [31] SCLK_GATING — Gating Special Clock(Max Clock = 200MHz) 0: Clock is OFF 1: Clock is ON.
    0=OFF (Clock is OFF); 1=ON (Clock is ON.)
  [17:16] CLK_SRC_SEL — 00: PLL_AUDIO(8X) 01: PLL_AUDIO(8X)/2 10: PLL_AUDIO(8X)/4 11: PLL_AUDIO.
    0=PLL_AUDIO_openingparen_8X_closingparen_ (PLL_AUDIO(8X)); 1=PLL_AUDIO_openingparen_8X_closingparen__slash_2 (PLL_AUDIO(8X)/2); 2=PLL_AUDIO_openingparen_8X_closingparen__slash_4 (PLL_AUDIO(8X)/4); 3=PLL_AUDIO
0xB8 I2S_PCM2_CLK_REG
  fields as I2S_PCM0_CLK_REG
0xBC AC97_CLK_REG reset 0x30000 — AC97 Clock Register
  [31] SCLK_GATING — Gating Special Clock(Max Clock = 200MHz) 0: Clock is OFF 1: Clock is ON
    0=OFF (Clock is OFF); 1=ON (Clock is ON)
  [17:16] CLK_SRC_SEL — 00: PLL_AUDIO(8x) 01: PLL_AUDIO(4X) 10: PLL_AUDIO(2X) 11: PLL_AUDIO(1X)
    0=PLL_AUDIO_openingparen_8x_closingparen_ (PLL_AUDIO(8x)); 1=PLL_AUDIO_openingparen_4X_closingparen_ (PLL_AUDIO(4X)); 2=PLL_AUDIO_openingparen_2X_closingparen_ (PLL_AUDIO(2X)); 3=PLL_AUDIO_openingparen_1X_closingparen_ (PLL_AUDIO(1X))
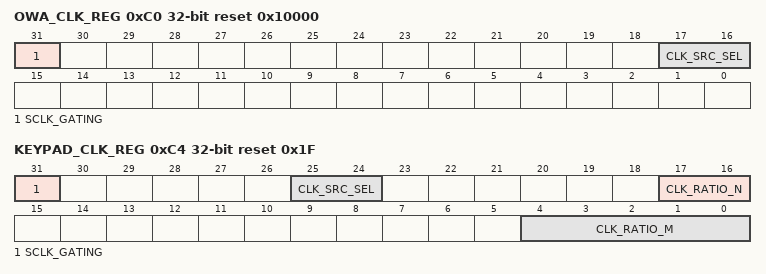
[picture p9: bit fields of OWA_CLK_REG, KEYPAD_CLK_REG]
0xC0 OWA_CLK_REG reset 0x10000 — OWA Clock Register
  [31] SCLK_GATING — Gating Special Clock(Max Clock = 200MHz) 0: Clock is OFF 1: Clock is ON
    0=OFF (Clock is OFF); 1=ON (Clock is ON)
  [17:16] CLK_SRC_SEL — 00: PLL_AUDIO(8X) 01: PLL_AUDIO(8X)/2 10: PLL_AUDIO(8X)/4 11: PLL_AUDIO.
    values as I2S_PCM1_CLK_REG.CLK_SRC_SEL
0xC4 KEYPAD_CLK_REG reset 0x1F — KEYPAD Clock Register
  [31] SCLK_GATING — Gating Special Clock(Max Clock = 100MHz) 0: Clock is OFF 1: Clock is ON This special clock = / / .
    0=OFF (Clock is OFF); 1=ON (Clock is ON This special clock = / / .)
  [25:24] CLK_SRC_SEL — Clock Source Select 00: OSC24M 01: / 10: LOSC 11: /
    0=OSC24M; 2=LOSC
  [17:16] CLK_RATIO_N — Clock pre-divide ratio (n) The select clock source is pre-divided by 2^n. The divider is 1/2/4/8.
  [4:0] CLK_RATIO_M — Clock divide ratio (m) The pre-divided clock is divided by (m+1). The divider is from 1 to 32.
